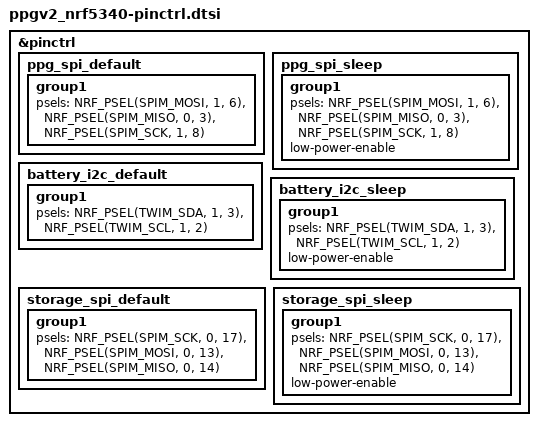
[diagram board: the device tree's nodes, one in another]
#include <zephyr/dt-bindings/pinctrl/nrf-pinctrl.h>

&pinctrl {
	ppg_spi_default: ppg_spi_default {
		group1 {
			psels = <NRF_PSEL(SPIM_MOSI, 1, 6)>,
				<NRF_PSEL(SPIM_MISO, 0, 3)>,
				<NRF_PSEL(SPIM_SCK, 1, 8)>;
		};
	};

	ppg_spi_sleep: ppg_spi_sleep {
		group1 {
			psels = <NRF_PSEL(SPIM_MOSI, 1, 6)>,
				<NRF_PSEL(SPIM_MISO, 0, 3)>,
				<NRF_PSEL(SPIM_SCK, 1, 8)>;
			low-power-enable;
		};
	};

	battery_i2c_default: battery_i2c_default {
		group1 {
			psels = <NRF_PSEL(TWIM_SDA, 1, 3)>,
				<NRF_PSEL(TWIM_SCL, 1, 2)>;
		};
	};

	battery_i2c_sleep: battery_i2c_sleep {
		group1 {
			psels = <NRF_PSEL(TWIM_SDA, 1, 3)>,
				<NRF_PSEL(TWIM_SCL, 1, 2)>;
			low-power-enable;
		};
	};

	storage_spi_default: storage_spi_default {
		group1 {
			psels = <NRF_PSEL(SPIM_SCK, 0, 17)>,
				<NRF_PSEL(SPIM_MOSI, 0, 13)>,
				<NRF_PSEL(SPIM_MISO, 0, 14)>;
		};
	};

	storage_spi_sleep: storage_spi_sleep {
		group1 {
			psels = <NRF_PSEL(SPIM_SCK, 0, 17)>,
				<NRF_PSEL(SPIM_MOSI, 0, 13)>,
				<NRF_PSEL(SPIM_MISO, 0, 14)>;
			low-power-enable;
		};
	};
};
